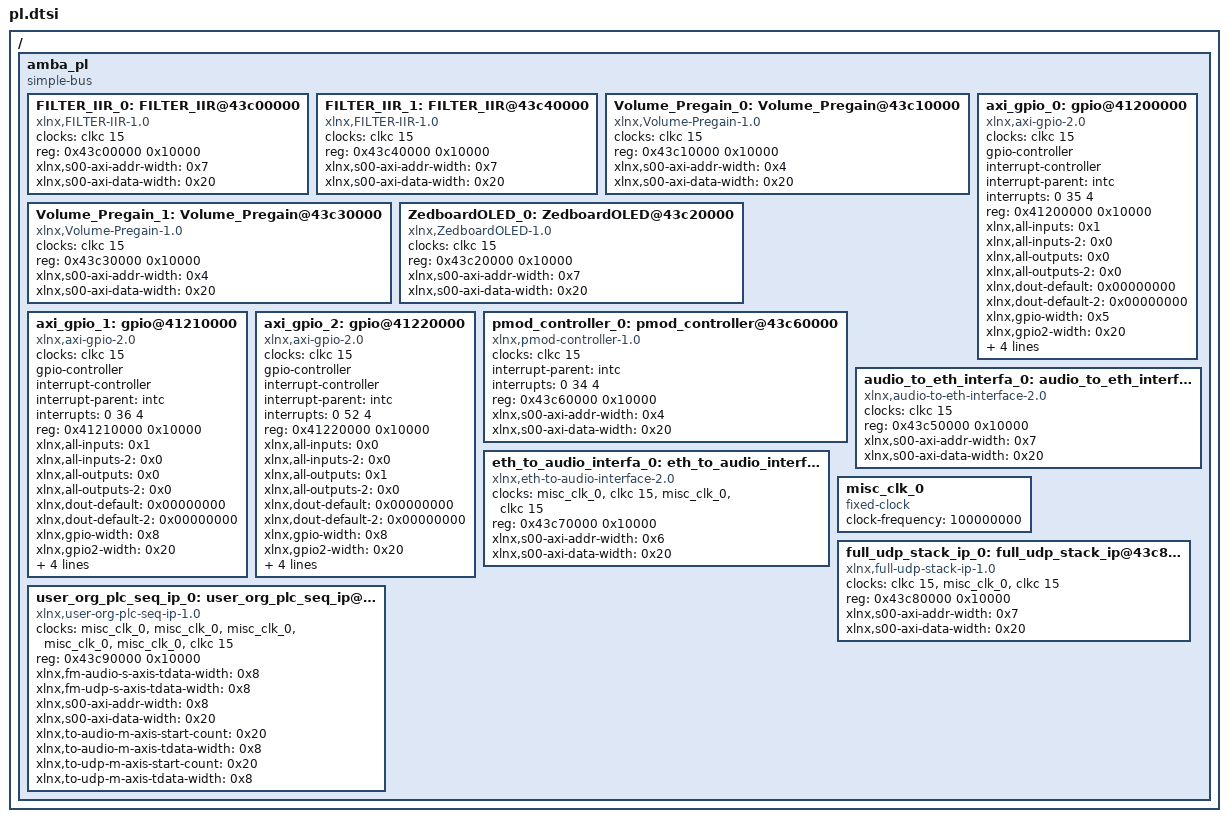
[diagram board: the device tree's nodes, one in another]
/*
 * CAUTION: This file is automatically generated by Xilinx.
 * Version: XSCT 2018.3
 * Today is: Sat Sep 28 16:57:36 2019
 */


/ {
	amba_pl: amba_pl {
		#address-cells = <1>;
		#size-cells = <1>;
		compatible = "simple-bus";
		ranges ;
		FILTER_IIR_0: FILTER_IIR@43c00000 {
			/* This is a place holder node for a custom IP, user may need to update the entries */
			clock-names = "s00_axi_aclk";
			clocks = <&clkc 15>;
			compatible = "xlnx,FILTER-IIR-1.0";
			reg = <0x43c00000 0x10000>;
			xlnx,s00-axi-addr-width = <0x7>;
			xlnx,s00-axi-data-width = <0x20>;
		};
		FILTER_IIR_1: FILTER_IIR@43c40000 {
			/* This is a place holder node for a custom IP, user may need to update the entries */
			clock-names = "s00_axi_aclk";
			clocks = <&clkc 15>;
			compatible = "xlnx,FILTER-IIR-1.0";
			reg = <0x43c40000 0x10000>;
			xlnx,s00-axi-addr-width = <0x7>;
			xlnx,s00-axi-data-width = <0x20>;
		};
		Volume_Pregain_0: Volume_Pregain@43c10000 {
			/* This is a place holder node for a custom IP, user may need to update the entries */
			clock-names = "s00_axi_aclk";
			clocks = <&clkc 15>;
			compatible = "xlnx,Volume-Pregain-1.0";
			reg = <0x43c10000 0x10000>;
			xlnx,s00-axi-addr-width = <0x4>;
			xlnx,s00-axi-data-width = <0x20>;
		};
		Volume_Pregain_1: Volume_Pregain@43c30000 {
			/* This is a place holder node for a custom IP, user may need to update the entries */
			clock-names = "s00_axi_aclk";
			clocks = <&clkc 15>;
			compatible = "xlnx,Volume-Pregain-1.0";
			reg = <0x43c30000 0x10000>;
			xlnx,s00-axi-addr-width = <0x4>;
			xlnx,s00-axi-data-width = <0x20>;
		};
		ZedboardOLED_0: ZedboardOLED@43c20000 {
			/* This is a place holder node for a custom IP, user may need to update the entries */
			clock-names = "s00_axi_aclk";
			clocks = <&clkc 15>;
			compatible = "xlnx,ZedboardOLED-1.0";
			reg = <0x43c20000 0x10000>;
			xlnx,s00-axi-addr-width = <0x7>;
			xlnx,s00-axi-data-width = <0x20>;
		};
		axi_gpio_0: gpio@41200000 {
			#gpio-cells = <3>;
			#interrupt-cells = <2>;
			clock-names = "s_axi_aclk";
			clocks = <&clkc 15>;
			compatible = "xlnx,axi-gpio-2.0", "xlnx,xps-gpio-1.00.a";
			gpio-controller ;
			interrupt-controller ;
			interrupt-names = "ip2intc_irpt";
			interrupt-parent = <&intc>;
			interrupts = <0 35 4>;
			reg = <0x41200000 0x10000>;
			xlnx,all-inputs = <0x1>;
			xlnx,all-inputs-2 = <0x0>;
			xlnx,all-outputs = <0x0>;
			xlnx,all-outputs-2 = <0x0>;
			xlnx,dout-default = <0x00000000>;
			xlnx,dout-default-2 = <0x00000000>;
			xlnx,gpio-width = <0x5>;
			xlnx,gpio2-width = <0x20>;
			xlnx,interrupt-present = <0x1>;
			xlnx,is-dual = <0x0>;
			xlnx,tri-default = <0xFFFFFFFF>;
			xlnx,tri-default-2 = <0xFFFFFFFF>;
		};
		axi_gpio_1: gpio@41210000 {
			#gpio-cells = <3>;
			#interrupt-cells = <2>;
			clock-names = "s_axi_aclk";
			clocks = <&clkc 15>;
			compatible = "xlnx,axi-gpio-2.0", "xlnx,xps-gpio-1.00.a";
			gpio-controller ;
			interrupt-controller ;
			interrupt-names = "ip2intc_irpt";
			interrupt-parent = <&intc>;
			interrupts = <0 36 4>;
			reg = <0x41210000 0x10000>;
			xlnx,all-inputs = <0x1>;
			xlnx,all-inputs-2 = <0x0>;
			xlnx,all-outputs = <0x0>;
			xlnx,all-outputs-2 = <0x0>;
			xlnx,dout-default = <0x00000000>;
			xlnx,dout-default-2 = <0x00000000>;
			xlnx,gpio-width = <0x8>;
			xlnx,gpio2-width = <0x20>;
			xlnx,interrupt-present = <0x1>;
			xlnx,is-dual = <0x0>;
			xlnx,tri-default = <0xFFFFFFFF>;
			xlnx,tri-default-2 = <0xFFFFFFFF>;
		};
		axi_gpio_2: gpio@41220000 {
			#gpio-cells = <3>;
			#interrupt-cells = <2>;
			clock-names = "s_axi_aclk";
			clocks = <&clkc 15>;
			compatible = "xlnx,axi-gpio-2.0", "xlnx,xps-gpio-1.00.a";
			gpio-controller ;
			interrupt-controller ;
			interrupt-names = "ip2intc_irpt";
			interrupt-parent = <&intc>;
			interrupts = <0 52 4>;
			reg = <0x41220000 0x10000>;
			xlnx,all-inputs = <0x0>;
			xlnx,all-inputs-2 = <0x0>;
			xlnx,all-outputs = <0x1>;
			xlnx,all-outputs-2 = <0x0>;
			xlnx,dout-default = <0x00000000>;
			xlnx,dout-default-2 = <0x00000000>;
			xlnx,gpio-width = <0x8>;
			xlnx,gpio2-width = <0x20>;
			xlnx,interrupt-present = <0x1>;
			xlnx,is-dual = <0x0>;
			xlnx,tri-default = <0xFFFFFFFF>;
			xlnx,tri-default-2 = <0xFFFFFFFF>;
		};
		pmod_controller_0: pmod_controller@43c60000 {
			/* This is a place holder node for a custom IP, user may need to update the entries */
			clock-names = "s00_axi_aclk";
			clocks = <&clkc 15>;
			compatible = "xlnx,pmod-controller-1.0";
			interrupt-names = "Rotary_event";
			interrupt-parent = <&intc>;
			interrupts = <0 34 4>;
			reg = <0x43c60000 0x10000>;
			xlnx,s00-axi-addr-width = <0x4>;
			xlnx,s00-axi-data-width = <0x20>;
		};
		audio_to_eth_interfa_0: audio_to_eth_interface@43c50000 {
			/* This is a place holder node for a custom IP, user may need to update the entries */
			clock-names = "s00_axi_aclk";
			clocks = <&clkc 15>;
			compatible = "xlnx,audio-to-eth-interface-2.0";
			reg = <0x43c50000 0x10000>;
			xlnx,s00-axi-addr-width = <0x7>;
			xlnx,s00-axi-data-width = <0x20>;
		};
		eth_to_audio_interfa_0: eth_to_audio_interface@43c70000 {
			/* This is a place holder node for a custom IP, user may need to update the entries */
			clock-names = "s00_axi_aclk";
			clocks = <&misc_clk_0>, <&clkc 15>, <&misc_clk_0>, <&clkc 15>;
			compatible = "xlnx,eth-to-audio-interface-2.0";
			reg = <0x43c70000 0x10000>;
			xlnx,s00-axi-addr-width = <0x6>;
			xlnx,s00-axi-data-width = <0x20>;
		};
		misc_clk_0: misc_clk_0 {
			#clock-cells = <0>;
			clock-frequency = <100000000>;
			compatible = "fixed-clock";
		};
		full_udp_stack_ip_0: full_udp_stack_ip@43c80000 {
			/* This is a place holder node for a custom IP, user may need to update the entries */
			clock-names = "clk phy_rx_clk s00_axi_aclk";
			clocks = <&clkc 15>, <&misc_clk_0>, <&clkc 15>;
			compatible = "xlnx,full-udp-stack-ip-1.0";
			reg = <0x43c80000 0x10000>;
			xlnx,s00-axi-addr-width = <0x7>;
			xlnx,s00-axi-data-width = <0x20>;
		};
		user_org_plc_seq_ip_0: user_org_plc_seq_ip@43c90000 {
			/* This is a place holder node for a custom IP, user may need to update the entries */
			clock-names = "clk_125 fm_udp_s_axis_aclk fm_audio_s_axis_aclk to_udp_m_axis_aclk to_audio_m_axis_aclk s00_axi_aclk";
			clocks = <&misc_clk_0>, <&misc_clk_0>, <&misc_clk_0>, <&misc_clk_0>, <&misc_clk_0>, <&clkc 15>;
			compatible = "xlnx,user-org-plc-seq-ip-1.0";
			reg = <0x43c90000 0x10000>;
			xlnx,fm-audio-s-axis-tdata-width = <0x8>;
			xlnx,fm-udp-s-axis-tdata-width = <0x8>;
			xlnx,s00-axi-addr-width = <0x8>;
			xlnx,s00-axi-data-width = <0x20>;
			xlnx,to-audio-m-axis-start-count = <0x20>;
			xlnx,to-audio-m-axis-tdata-width = <0x8>;
			xlnx,to-udp-m-axis-start-count = <0x20>;
			xlnx,to-udp-m-axis-tdata-width = <0x8>;
		};
	};
};
